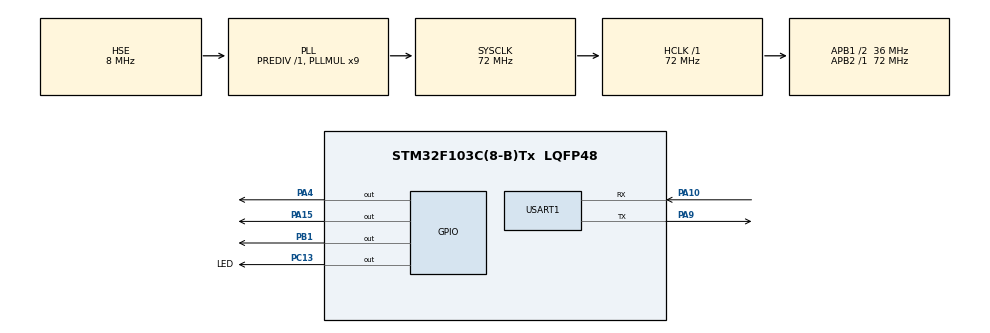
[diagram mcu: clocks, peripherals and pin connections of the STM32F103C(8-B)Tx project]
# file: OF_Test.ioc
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Mcu.Family=STM32F1
RCC.PLLSourceVirtual=RCC_PLLSOURCE_HSE
NVIC.DMA1_Channel5_IRQn=true\:0\:0\:false\:false\:true\:false\:true
PD1-OSC_OUT.Mode=HSE-External-Oscillator
Dma.USART1_RX.0.PeriphDataAlignment=DMA_PDATAALIGN_BYTE
PA10.Mode=Asynchronous
PC13-TAMPER-RTC.Signal=GPIO_Output
PD0-OSC_IN.Signal=RCC_OSC_IN
RCC.APB1CLKDivider=RCC_HCLK_DIV2
RCC.SYSCLKSource=RCC_SYSCLKSOURCE_PLLCLK
ProjectManager.StackSize=0x400
PD1-OSC_OUT.Signal=RCC_OSC_OUT
PA13.Signal=SYS_JTMS-SWDIO
PA9.Mode=Asynchronous
ProjectManager.TargetToolchain=STM32CubeIDE
Dma.USART1_RX.0.Direction=DMA_PERIPH_TO_MEMORY
RCC.HCLKFreq_Value=72000000
RCC.APB2TimFreq_Value=72000000
TIM3.Period=65535
PA9.Signal=USART1_TX
RCC.USBFreq_Value=72000000
TIM4.Prescaler=32000-1
RCC.AHBFreq_Value=72000000
Dma.USART1_RX.0.PeriphInc=DMA_PINC_DISABLE
Dma.USART1_RX.0.Priority=DMA_PRIORITY_LOW
PD0-OSC_IN.Mode=HSE-External-Oscillator
PB3.Mode=Trace_Asynchronous_SW
board=custom
PC13-TAMPER-RTC.GPIO_Label=LED
RCC.PLLMUL=RCC_PLL_MUL9
RCC.APB2Freq_Value=72000000
VP_TIM2_VS_ClockSourceINT.Mode=Internal
PA14.Mode=Trace_Asynchronous_SW
TIM3.Prescaler=72-1
Dma.USART1_RX.0.MemDataAlignment=DMA_MDATAALIGN_BYTE
TIM2.Period=5000
TIM4.Period=1000
Dma.USART1_RX.0.MemInc=DMA_MINC_ENABLE
PA13.Mode=Trace_Asynchronous_SW
Mcu.Name=STM32F103C(8-B)Tx
PB3.Signal=SYS_JTDO-TRACESWO
PA4.Signal=GPIO_Output
RCC.SYSCLKFreq_VALUE=72000000
Mcu.Package=LQFP48
TIM2.Prescaler=72-1
PB1.Signal=GPIO_Output
USART1.VirtualMode=VM_ASYNC
PA10.Signal=USART1_RX
PA14.Signal=SYS_JTCK-SWCLK
PA15.Signal=GPIO_Output
ProjectManager.HeapSize=0x200
VP_TIM4_VS_ClockSourceINT.Mode=Internal
NVIC.PriorityGroup=NVIC_PRIORITYGROUP_4
RCC.APB1TimFreq_Value=72000000
Dma.USART1_RX.0.Mode=DMA_CIRCULAR
NVIC.USART1_IRQn=true\:0\:0\:false\:false\:true\:true\:true
Dma.Request0=USART1_RX
RCC.APB1Freq_Value=36000000
Dma.USART1_RX.0.Instance=DMA1_Channel5
VP_TIM3_VS_ClockSourceINT.Mode=Internal

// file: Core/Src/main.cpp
/* USER CODE BEGIN Header */
/**
  ******************************************************************************
  * @file           : main.c
  * @brief          : Main program body
  ******************************************************************************
  * @attention
  *
  * <h2><center>&copy; Copyright (c) 2023 STMicroelectronics.
  * All rights reserved.</center></h2>
  *
  * This software component is licensed by ST under BSD 3-Clause license,
  * the "License"; You may not use this file except in compliance with the
  * License. You may obtain a copy of the License at:
  *                        opensource.org/licenses/BSD-3-Clause
  *
  ******************************************************************************
  */
/* USER CODE END Header */
#include "main.h"
#include "dma.h"
#include "tim.h"
#include "usart.h"
#include "gpio.h"

/* USER CODE BEGIN Includes */
#include "mspv2.hpp"
/* USER CODE END Includes */

/* USER CODE BEGIN PV */
MatekOF matek_of;
/* USER CODE END PV */

void SystemClock_Config(void);

/* USER CODE BEGIN 0 */

void HAL_UART_RxCpltCallback(UART_HandleTypeDef *huart)
{
	if(huart->Instance == matek_of.huart_of.Instance) {
		matek_of.MatekRead2();
	}

}
/* USER CODE END 0 */

int main(void)
{

  /* MCU Configuration--------------------------------------------------------*/

  /* Reset of all peripherals, Initializes the Flash interface and the Systick. */
  HAL_Init();

  /* Configure the system clock */
  SystemClock_Config();

  /* Initialize all configured peripherals */
  MX_GPIO_Init();
  MX_DMA_Init();
  MX_TIM2_Init();
  MX_TIM3_Init();
  MX_TIM4_Init();
  MX_USART1_UART_Init();
  /* USER CODE BEGIN 2 */
  matek_of.begin(huart1);
  matek_of.MatekRead2();
  /* USER CODE END 2 */

  /* Infinite loop */
  while (1)
  {

  }
}

void SystemClock_Config(void)
{
  RCC_OscInitTypeDef RCC_OscInitStruct = {0};
  RCC_ClkInitTypeDef RCC_ClkInitStruct = {0};

  /** Initializes the RCC Oscillators according to the specified parameters
  * in the RCC_OscInitTypeDef structure.
  */
  RCC_OscInitStruct.OscillatorType = RCC_OSCILLATORTYPE_HSE;
  RCC_OscInitStruct.HSEState = RCC_HSE_ON;
  RCC_OscInitStruct.HSEPredivValue = RCC_HSE_PREDIV_DIV1;
  RCC_OscInitStruct.HSIState = RCC_HSI_ON;
  RCC_OscInitStruct.PLL.PLLState = RCC_PLL_ON;
  RCC_OscInitStruct.PLL.PLLSource = RCC_PLLSOURCE_HSE;
  RCC_OscInitStruct.PLL.PLLMUL = RCC_PLL_MUL9;
  if (HAL_RCC_OscConfig(&RCC_OscInitStruct) != HAL_OK)
  {
    Error_Handler();
  }
  /** Initializes the CPU, AHB and APB buses clocks
  */
  RCC_ClkInitStruct.ClockType = RCC_CLOCKTYPE_HCLK|RCC_CLOCKTYPE_SYSCLK
                              |RCC_CLOCKTYPE_PCLK1|RCC_CLOCKTYPE_PCLK2;
  RCC_ClkInitStruct.SYSCLKSource = RCC_SYSCLKSOURCE_PLLCLK;
  RCC_ClkInitStruct.AHBCLKDivider = RCC_SYSCLK_DIV1;
  RCC_ClkInitStruct.APB1CLKDivider = RCC_HCLK_DIV2;
  RCC_ClkInitStruct.APB2CLKDivider = RCC_HCLK_DIV1;

  if (HAL_RCC_ClockConfig(&RCC_ClkInitStruct, FLASH_LATENCY_2) != HAL_OK)
  {
    Error_Handler();
  }
}

void Error_Handler(void)
{
  __disable_irq();
  while (1)
  {
  }
}

/************************ (C) COPYRIGHT STMicroelectronics *****END OF FILE****/
